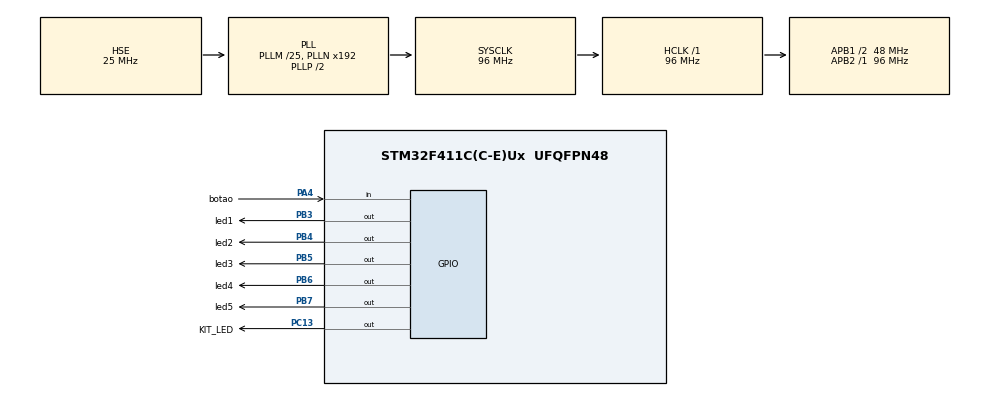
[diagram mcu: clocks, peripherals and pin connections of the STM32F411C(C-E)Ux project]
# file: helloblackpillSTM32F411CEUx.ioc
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Mcu.Family=STM32F4
Mcu.Name=STM32F411C(C-E)Ux
Mcu.Package=UFQFPN48
NVIC.PriorityGroup=NVIC_PRIORITYGROUP_4
PA13.Mode=Serial_Wire
PA13.Signal=SYS_JTMS-SWDIO
PA14.Mode=Serial_Wire
PA14.Signal=SYS_JTCK-SWCLK
PA4.GPIO_Label=botao
PA4.Signal=GPIO_Input
PB3.GPIO_Label=led1
PB3.Signal=GPIO_Output
PB4.GPIO_Label=led2
PB4.Signal=GPIO_Output
PB5.GPIO_Label=led3
PB5.Signal=GPIO_Output
PB6.GPIO_Label=led4
PB6.Signal=GPIO_Output
PB7.GPIO_Label=led5
PB7.Signal=GPIO_Output
PC13-ANTI_TAMP.GPIO_Label=KIT_LED
PC13-ANTI_TAMP.Signal=GPIO_Output
PC14-OSC32_IN.Mode=LSE-External-Oscillator
PC14-OSC32_IN.Signal=RCC_OSC32_IN
PC15-OSC32_OUT.Mode=LSE-External-Oscillator
PC15-OSC32_OUT.Signal=RCC_OSC32_OUT
PH0\ -\ OSC_IN.Mode=HSE-External-Oscillator
PH0\ -\ OSC_IN.Signal=RCC_OSC_IN
PH1\ -\ OSC_OUT.Mode=HSE-External-Oscillator
PH1\ -\ OSC_OUT.Signal=RCC_OSC_OUT
ProjectManager.HeapSize=0x200
ProjectManager.StackSize=0x400
ProjectManager.TargetToolchain=Makefile
RCC.48MHZClocksFreq_Value=48000000
RCC.AHBFreq_Value=96000000
RCC.APB1CLKDivider=RCC_HCLK_DIV2
RCC.APB1Freq_Value=48000000
RCC.APB1TimFreq_Value=96000000
RCC.APB2Freq_Value=96000000
RCC.APB2TimFreq_Value=96000000
RCC.CortexFreq_Value=96000000
RCC.HCLKFreq_Value=96000000
RCC.HSE_VALUE=25000000
RCC.HSI_VALUE=16000000
RCC.PLLM=25
RCC.PLLSourceVirtual=RCC_PLLSOURCE_HSE
RCC.SYSCLKFreq_VALUE=96000000
RCC.SYSCLKSource=RCC_SYSCLKSOURCE_PLLCLK
RCC.VCOOutputFreq_Value=192000000
board=custom

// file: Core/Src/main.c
/* USER CODE BEGIN Header */
/**
  ******************************************************************************
  * @file           : main.c
  * @brief          : Main program body
  ******************************************************************************
  * @attention
  *
  * Copyright (c) 2022 STMicroelectronics.
  * All rights reserved.
  *
  * This software is licensed under terms that can be found in the LICENSE file
  * in the root directory of this software component.
  * If no LICENSE file comes with this software, it is provided AS-IS.
  *
  ******************************************************************************
  */
/* USER CODE END Header */
#include "main.h"
#include "button.h"

/* USER CODE BEGIN PV */
uint16_t contagem=0;
/* USER CODE END PV */

void SystemClock_Config(void);
static void MX_GPIO_Init(void);

int main(void)
{
  /* USER CODE BEGIN 1 */
  uint32_t i;
  /* USER CODE END 1 */

  /* MCU Configuration--------------------------------------------------------*/

  /* Reset of all peripherals, Initializes the Flash interface and the Systick. */
  HAL_Init();

  /* Configure the system clock */
  SystemClock_Config();

  /* Initialize all configured peripherals */
  MX_GPIO_Init();

  /* Infinite loop */
  /* USER CODE BEGIN WHILE */

  while (1)
  {
    for(i=0;i<15;i++){

      if (button_release(GPIOA, botao_Pin,0)){
         contagem++;
         contagem&=0b00011111;
         HAL_GPIO_WritePin(GPIOB,led1_Pin,(contagem>>0)&1);
         HAL_GPIO_WritePin(GPIOB,led2_Pin,(contagem>>1)&1);
         HAL_GPIO_WritePin(GPIOB,led3_Pin,(contagem>>2)&1);
         HAL_GPIO_WritePin(GPIOB,led4_Pin,(contagem>>3)&1);
         HAL_GPIO_WritePin(GPIOB,led5_Pin,(contagem>>4)&1);

      }
      HAL_Delay(27);

    }
    HAL_GPIO_TogglePin(KIT_LED_GPIO_Port, KIT_LED_Pin);

    /* USER CODE END WHILE */

  }
}

void SystemClock_Config(void)
{
  RCC_OscInitTypeDef RCC_OscInitStruct = {0};
  RCC_ClkInitTypeDef RCC_ClkInitStruct = {0};

  /** Configure the main internal regulator output voltage
  */
  __HAL_RCC_PWR_CLK_ENABLE();
  __HAL_PWR_VOLTAGESCALING_CONFIG(PWR_REGULATOR_VOLTAGE_SCALE1);

  /** Initializes the RCC Oscillators according to the specified parameters
  * in the RCC_OscInitTypeDef structure.
  */
  RCC_OscInitStruct.OscillatorType = RCC_OSCILLATORTYPE_HSE;
  RCC_OscInitStruct.HSEState = RCC_HSE_ON;
  RCC_OscInitStruct.PLL.PLLState = RCC_PLL_ON;
  RCC_OscInitStruct.PLL.PLLSource = RCC_PLLSOURCE_HSE;
  RCC_OscInitStruct.PLL.PLLM = 25;
  RCC_OscInitStruct.PLL.PLLN = 192;
  RCC_OscInitStruct.PLL.PLLP = RCC_PLLP_DIV2;
  RCC_OscInitStruct.PLL.PLLQ = 4;
  if (HAL_RCC_OscConfig(&RCC_OscInitStruct) != HAL_OK)
  {
    Error_Handler();
  }

  /** Initializes the CPU, AHB and APB buses clocks
  */
  RCC_ClkInitStruct.ClockType = RCC_CLOCKTYPE_HCLK|RCC_CLOCKTYPE_SYSCLK
                              |RCC_CLOCKTYPE_PCLK1|RCC_CLOCKTYPE_PCLK2;
  RCC_ClkInitStruct.SYSCLKSource = RCC_SYSCLKSOURCE_PLLCLK;
  RCC_ClkInitStruct.AHBCLKDivider = RCC_SYSCLK_DIV1;
  RCC_ClkInitStruct.APB1CLKDivider = RCC_HCLK_DIV2;
  RCC_ClkInitStruct.APB2CLKDivider = RCC_HCLK_DIV1;

  if (HAL_RCC_ClockConfig(&RCC_ClkInitStruct, FLASH_LATENCY_3) != HAL_OK)
  {
    Error_Handler();
  }
}

static void MX_GPIO_Init(void)
{
  GPIO_InitTypeDef GPIO_InitStruct = {0};

  /* GPIO Ports Clock Enable */
  __HAL_RCC_GPIOC_CLK_ENABLE();
  __HAL_RCC_GPIOH_CLK_ENABLE();
  __HAL_RCC_GPIOA_CLK_ENABLE();
  __HAL_RCC_GPIOB_CLK_ENABLE();

  /*Configure GPIO pin Output Level */
  HAL_GPIO_WritePin(KIT_LED_GPIO_Port, KIT_LED_Pin, GPIO_PIN_RESET);

  /*Configure GPIO pin Output Level */
  HAL_GPIO_WritePin(GPIOB, led1_Pin|led2_Pin|led3_Pin|led4_Pin
                          |led5_Pin, GPIO_PIN_RESET);

  /*Configure GPIO pin : KIT_LED_Pin */
  GPIO_InitStruct.Pin = KIT_LED_Pin;
  GPIO_InitStruct.Mode = GPIO_MODE_OUTPUT_PP;
  GPIO_InitStruct.Pull = GPIO_NOPULL;
  GPIO_InitStruct.Speed = GPIO_SPEED_FREQ_LOW;
  HAL_GPIO_Init(KIT_LED_GPIO_Port, &GPIO_InitStruct);

  /*Configure GPIO pin : botao_Pin */
  GPIO_InitStruct.Pin = botao_Pin;
  GPIO_InitStruct.Mode = GPIO_MODE_INPUT;
  GPIO_InitStruct.Pull = GPIO_NOPULL;
  HAL_GPIO_Init(botao_GPIO_Port, &GPIO_InitStruct);

  /*Configure GPIO pins : led1_Pin led2_Pin led3_Pin led4_Pin
                           led5_Pin */
  GPIO_InitStruct.Pin = led1_Pin|led2_Pin|led3_Pin|led4_Pin
                          |led5_Pin;
  GPIO_InitStruct.Mode = GPIO_MODE_OUTPUT_PP;
  GPIO_InitStruct.Pull = GPIO_NOPULL;
  GPIO_InitStruct.Speed = GPIO_SPEED_FREQ_LOW;
  HAL_GPIO_Init(GPIOB, &GPIO_InitStruct);

}

void Error_Handler(void)
{
  __disable_irq();
  while (1)
  {
  }
}
